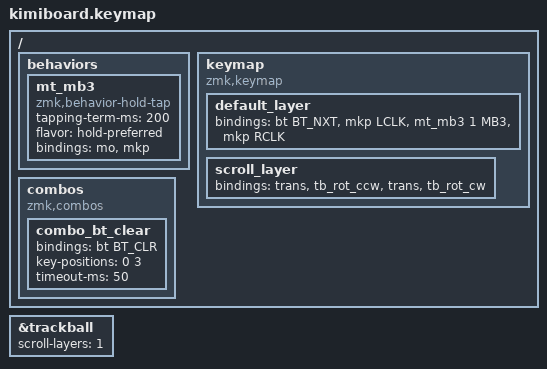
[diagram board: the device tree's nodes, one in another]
#include <behaviors.dtsi>
#include <dt-bindings/zmk/bt.h>
#include <dt-bindings/zmk/keys.h>
#include <dt-bindings/zmk/mouse.h>
#include <behaviors/rgbled_widget.dtsi>
#include <dt-bindings/zmk/kimiboard.h>

&trackball {
    scroll-layers = <1>;
};

/ {
    behaviors {
        mt_mb3: mt_mb3 {
            compatible = "zmk,behavior-hold-tap";
            #binding-cells = <2>;
            tapping-term-ms = <200>;
            flavor = "hold-preferred";
            bindings = <&mo>, <&mkp>;
        };
    };
    keymap {
        compatible = "zmk,keymap";

        default_layer {
            bindings = <
                &bt BT_NXT  &mkp LCLK  &mt_mb3 1 MB3  &mkp RCLK
            >;
        };

        scroll_layer {
            bindings = <
                &trans    &tb_rot_ccw    &trans    &tb_rot_cw
            >;
        };
    };

    combos {
        compatible = "zmk,combos";

        combo_bt_clear {
            bindings = <&bt BT_CLR>;
            key-positions = <0 3>;
            timeout-ms = <50>;
        };
    };

};
